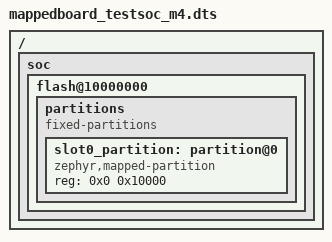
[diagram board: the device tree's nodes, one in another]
/dts-v1/;
/ {
	soc {
		flash@10000000 {
			partitions {
				compatible = "fixed-partitions";
				ranges;
				slot0_partition: partition@0 {
					compatible = "zephyr,mapped-partition";
					reg = < 0x0 0x10000 >;
				};
			};
		};
	};
};
